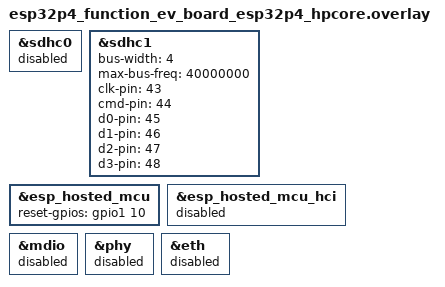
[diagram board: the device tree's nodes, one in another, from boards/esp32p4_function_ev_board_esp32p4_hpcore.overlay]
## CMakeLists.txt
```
cmake_minimum_required(VERSION 3.20.0)

find_package(Zephyr REQUIRED HINTS $ENV{ZEPHYR_BASE})
project(stamp_p4_p1)

target_sources(app PRIVATE src/main.c)
```

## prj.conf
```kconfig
# Stamp-P4 Stamp-P4 P1 is a temporary control image.
CONFIG_NETWORKING=y
CONFIG_WIFI=y
CONFIG_WIFI_USAGE_MODE_STA=y
CONFIG_WIFI_ESP_HOSTED_MCU=y

# ESP-Hosted-MCU source 3f0d107 reports v2.12.12.
CONFIG_ESP_HOSTED_MCU_FW_VERSION_MAJOR=2
CONFIG_ESP_HOSTED_MCU_FW_VERSION_MINOR=12
CONFIG_ESP_HOSTED_MCU_FW_VERSION_PATCH=12
CONFIG_ESP_HOSTED_MCU_P1_TRANSPORT_TEST=y
CONFIG_ESP_HOSTED_MCU_LOG_LEVEL_INF=y

# IPv4/DHCP/ICMP are the only network functions needed by P1.
CONFIG_NET_IPV4=y
CONFIG_NET_IPV6=n
CONFIG_NET_ARP=y
CONFIG_NET_UDP=y
CONFIG_NET_DHCPV4=y
CONFIG_WIFI_STA_AUTO_DHCPV4=y
CONFIG_NET_MGMT_EVENT_INFO=y
CONFIG_NET_MGMT_EVENT_QUEUE_SIZE=32
CONFIG_NET_MGMT_EVENT_QUEUE_TIMEOUT=5000

# Leave enough room for Wi-Fi RPC events and 1500-byte data frames.
CONFIG_MAIN_STACK_SIZE=8192
CONFIG_SHELL_STACK_SIZE=6144
CONFIG_NET_RX_STACK_SIZE=4096
CONFIG_NET_TX_STACK_SIZE=2048
CONFIG_NET_MGMT_EVENT_STACK_SIZE=4096
CONFIG_NET_PKT_RX_COUNT=32
CONFIG_NET_PKT_TX_COUNT=24
CONFIG_NET_BUF_RX_COUNT=48
CONFIG_NET_BUF_TX_COUNT=32

# USB Serial/JTAG is the Function-EV board's selected console. The transport
# driver runs before the shell backend (priority 85 vs 90), so retain its
# startup markers until the shell can emit them.
CONFIG_LOG=y
CONFIG_LOG_MODE_DEFERRED=y
CONFIG_LOG_DEFAULT_LEVEL=3
CONFIG_SHELL=y
CONFIG_SHELL_BACKEND_SERIAL=y
CONFIG_SHELL_CMD_BUFF_SIZE=256
CONFIG_EARLY_CONSOLE=y
```

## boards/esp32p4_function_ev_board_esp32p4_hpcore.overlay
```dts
/*
 * Stamp-P4 P1 overlay.
 *
 * The Function-EV HP-core board support remains the base.  Only the
 * Stamp-P4 carrier wiring is changed here; this is not a copied board DTS.
 */

#include <zephyr/dt-bindings/gpio/gpio.h>

/* The Function-EV SD-card connector is not populated on Stamp-P4. */
&sdhc0 {
	status = "disabled";
};

/*
 * Stamp-AddOn C6 SDIO wiring on the Stamp-P4 carrier.
 *
 * GPIO42 is physical P4 GPIO42, represented by GPIO controller gpio1 offset
 * 10.  It is the C6 regulator enable/power-gate and reset-control path:
 * logical high enables the C6 rail, while logical low removes it.
 */
&sdhc1 {
	status = "okay";
	bus-width = <4>;
	max-bus-freq = <40000000>;
	clk-pin = <43>;
	cmd-pin = <44>;
	d0-pin = <45>;
	d1-pin = <46>;
	d2-pin = <47>;
	d3-pin = <48>;
};

&esp_hosted_mcu {
	reset-gpios = <&gpio1 10 GPIO_ACTIVE_HIGH>;
	status = "okay";
};

/* Bluetooth is outside P1 and is deliberately not brought up. */
&esp_hosted_mcu_hci {
	status = "disabled";
};

/* Ethernet is unrelated to this independent Wi-Fi host validation. */
&mdio {
	status = "disabled";
};

&phy {
	status = "disabled";
};

&eth {
	status = "disabled";
};
```

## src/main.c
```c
/*
 * Stamp-P4 P1 control application.
 *
 * P1 intentionally stops at the ESP-Hosted-MCU Wi-Fi path.  SSH, NTP, SMP,
 * and Bluetooth are not part of this image's acceptance claim.
 */

#include <errno.h>
#include <string.h>

#include <zephyr/kernel.h>
#include <zephyr/logging/log.h>
#include <zephyr/shell/shell.h>
#include <zephyr/sys/util.h>

#include <zephyr/net/icmp.h>
#include <zephyr/net/net_if.h>
#include <zephyr/net/net_ip.h>
#include <zephyr/net/net_mgmt.h>
#include <zephyr/net/wifi_mgmt.h>

LOG_MODULE_REGISTER(p1, LOG_LEVEL_INF);

#define P1_WIFI_EVENTS                                                                    \
	(NET_EVENT_WIFI_SCAN_RESULT | NET_EVENT_WIFI_SCAN_DONE |                          \
	 NET_EVENT_WIFI_CONNECT_RESULT | NET_EVENT_WIFI_DISCONNECT_RESULT)

static struct net_if *sta_iface;
static struct net_mgmt_event_callback wifi_cb;
static struct net_mgmt_event_callback ipv4_cb;

static uint32_t scan_result_count;
static bool scan_pending;
static bool connect_pending;
static bool associated;
static bool ipv4_ready;

static K_SEM_DEFINE(ping_reply_sem, 0, 1);
static struct net_icmp_ctx ping_ctx;

static int wifi_event_status(const struct net_mgmt_event_callback *cb)
{
	if (cb->info != NULL && cb->info_length >= sizeof(struct wifi_status)) {
		const struct wifi_status *status = cb->info;

		return status->status;
	}

	return -EIO;
}

static void p1_wifi_event_handler(struct net_mgmt_event_callback *cb,
				  uint64_t mgmt_event, struct net_if *iface)
{
	if (iface != sta_iface) {
		return;
	}

	switch (mgmt_event) {
	case NET_EVENT_WIFI_SCAN_RESULT: {
		const struct wifi_scan_result *result = cb->info;

		if (result == NULL ||
		    cb->info_length < sizeof(struct wifi_scan_result)) {
			LOG_ERR("P1 WIFI_SCAN_RESULT FAIL malformed");
			return;
		}

		scan_result_count++;
		LOG_INF("P1 WIFI_SCAN_RESULT index=%u ssid=%.*s channel=%u rssi=%d",
			scan_result_count, result->ssid_length,
			(const char *)result->ssid, result->channel, result->rssi);
		break;
	}

	case NET_EVENT_WIFI_SCAN_DONE: {
		int status = wifi_event_status(cb);

		scan_pending = false;
		if (status == 0) {
			LOG_INF("P1 STEP 09 WIFI_SCAN PASS results=%u",
				scan_result_count);
		} else {
			LOG_ERR("P1 STEP 09 WIFI_SCAN FAIL status=%d results=%u",
				status, scan_result_count);
		}
		break;
	}

	case NET_EVENT_WIFI_CONNECT_RESULT: {
		int status = wifi_event_status(cb);

		connect_pending = false;
		associated = (status == 0);
		ipv4_ready = false;
		if (associated) {
			LOG_INF("P1 STEP 10 ASSOCIATION PASS");
		} else {
			LOG_ERR("P1 STEP 10 ASSOCIATION FAIL status=%d", status);
		}
		break;
	}

	case NET_EVENT_WIFI_DISCONNECT_RESULT:
		associated = false;
		ipv4_ready = false;
		LOG_INF("P1 WIFI_DISCONNECT");
		break;

	default:
		break;
	}
}

static void p1_ipv4_event_handler(struct net_mgmt_event_callback *cb,
				  uint64_t mgmt_event, struct net_if *iface)
{
	char address[NET_IPV4_ADDR_LEN];
	struct net_in_addr *addr;

	ARG_UNUSED(cb);

	if (mgmt_event != NET_EVENT_IPV4_ADDR_ADD || iface != sta_iface) {
		return;
	}

	addr = net_if_ipv4_get_global_addr(iface, NET_ADDR_PREFERRED);
	if (addr == NULL) {
		LOG_ERR("P1 IPV4 FAIL no_preferred_address");
		return;
	}

	ipv4_ready = true;
	LOG_INF("P1 IPV4 PASS address=%s",
		net_addr_ntop(NET_AF_INET, addr, address, sizeof(address)));
}

static int cmd_p1_scan(const struct shell *sh, size_t argc, char **argv)
{
	struct wifi_scan_params params = {0};
	int ret;

	ARG_UNUSED(argc);
	ARG_UNUSED(argv);

	if (sta_iface == NULL) {
		shell_error(sh, "Wi-Fi station interface is not ready");
		return -ENODEV;
	}
	if (scan_pending) {
		shell_error(sh, "scan already pending");
		return -EBUSY;
	}

	scan_result_count = 0;
	scan_pending = true;
	params.scan_type = WIFI_SCAN_TYPE_ACTIVE;
	params.bands = BIT(WIFI_FREQ_BAND_2_4_GHZ);
	params.max_bss_cnt = 0;

	LOG_INF("P1 STEP 09 WIFI_SCAN BEGIN");
	ret = net_mgmt(NET_REQUEST_WIFI_SCAN, sta_iface, &params, sizeof(params));
	if (ret != 0) {
		scan_pending = false;
		LOG_ERR("P1 STEP 09 WIFI_SCAN FAIL request_errno=%d", ret);
		shell_error(sh, "scan request failed: %d", ret);
		return ret;
	}

	shell_print(sh, "scan requested");
	return 0;
}

static int cmd_p1_connect(const struct shell *sh, size_t argc, char **argv)
{
	struct wifi_connect_req_params params = {0};
	size_t ssid_len = strlen(argv[1]);
	size_t psk_len = argc >= 3 ? strlen(argv[2]) : 0;
	int ret;

	if (sta_iface == NULL) {
		shell_error(sh, "Wi-Fi station interface is not ready");
		return -ENODEV;
	}
	if (ssid_len == 0 || ssid_len > WIFI_SSID_MAX_LEN) {
		shell_error(sh, "SSID length must be 1..%u", WIFI_SSID_MAX_LEN);
		return -EINVAL;
	}
	if (psk_len > 64) {
		shell_error(sh, "PSK length must be <= 64");
		return -EINVAL;
	}
	if (connect_pending) {
		shell_error(sh, "connect already pending");
		return -EBUSY;
	}

	params.ssid = (const uint8_t *)argv[1];
	params.ssid_length = (uint8_t)ssid_len;
	params.psk = psk_len ? (const uint8_t *)argv[2] : NULL;
	params.psk_length = (uint8_t)psk_len;
	params.security = psk_len ? WIFI_SECURITY_TYPE_PSK : WIFI_SECURITY_TYPE_NONE;
	params.band = WIFI_FREQ_BAND_2_4_GHZ;
	params.channel = WIFI_CHANNEL_ANY;
	params.timeout = 30;

	connect_pending = true;
	LOG_INF("P1 STEP 10 ASSOCIATION BEGIN ssid_length=%u",
		(unsigned int)ssid_len);
	ret = net_mgmt(NET_REQUEST_WIFI_CONNECT, sta_iface, &params, sizeof(params));
	if (ret != 0) {
		connect_pending = false;
		LOG_ERR("P1 STEP 10 ASSOCIATION FAIL request_errno=%d", ret);
		shell_error(sh, "connect request failed: %d", ret);
		return ret;
	}

	shell_print(sh, "connect requested; wait for ASSOCIATION and IPV4 markers");
	return 0;
}

static enum net_verdict p1_ping_handler(struct net_icmp_ctx *ctx,
					struct net_pkt *pkt,
					struct net_icmp_ip_hdr *ip_hdr,
					struct net_icmp_hdr *icmp_hdr,
					void *user_data)
{
	ARG_UNUSED(ctx);
	ARG_UNUSED(pkt);
	ARG_UNUSED(ip_hdr);
	ARG_UNUSED(icmp_hdr);
	ARG_UNUSED(user_data);

	k_sem_give(&ping_reply_sem);
	return NET_OK;
}

static int cmd_p1_ping(const struct shell *sh, size_t argc, char **argv)
{
	struct net_sockaddr_in destination = {0};
	struct net_icmp_ping_params params = {0};
	int ret;

	ARG_UNUSED(argc);

	if (!associated || !ipv4_ready) {
		shell_error(sh, "association and DHCPv4 address are required first");
		LOG_ERR("P1 STEP 11 PING FAIL ipv4_not_ready");
		return -ENETDOWN;
	}

	destination.sin_family = NET_AF_INET;
	ret = net_addr_pton(NET_AF_INET, argv[1], &destination.sin_addr);
	if (ret != 0) {
		shell_error(sh, "invalid IPv4 address: %s", argv[1]);
		LOG_ERR("P1 STEP 11 PING FAIL invalid_target=%s", argv[1]);
		return -EINVAL;
	}

	params.identifier = 0x4553;
	params.sequence = 1;
	params.data_size = 16;
	k_sem_reset(&ping_reply_sem);

	LOG_INF("P1 STEP 11 PING BEGIN target=%s", argv[1]);
	ret = net_icmp_send_echo_request(&ping_ctx, sta_iface,
					 (struct net_sockaddr *)&destination,
					 &params, NULL);
	if (ret != 0) {
		LOG_ERR("P1 STEP 11 PING FAIL send_errno=%d", ret);
		shell_error(sh, "ping send failed: %d", ret);
		return ret;
	}

	if (k_sem_take(&ping_reply_sem, K_SECONDS(5)) != 0) {
		LOG_ERR("P1 STEP 11 PING FAIL timeout");
		shell_error(sh, "ping timeout");
		return -ETIMEDOUT;
	}

	LOG_INF("P1 STEP 11 PING PASS target=%s", argv[1]);
	shell_print(sh, "ping reply received");
	return 0;
}

static int cmd_p1_status(const struct shell *sh, size_t argc, char **argv)
{
	ARG_UNUSED(argc);
	ARG_UNUSED(argv);

	shell_print(sh, "sta=%s associated=%s ipv4=%s scan_pending=%s connect_pending=%s",
		    sta_iface != NULL ? "ready" : "missing",
		    associated ? "yes" : "no", ipv4_ready ? "yes" : "no",
		    scan_pending ? "yes" : "no", connect_pending ? "yes" : "no");
	return 0;
}

SHELL_STATIC_SUBCMD_SET_CREATE(p1_commands,
	SHELL_CMD_ARG(scan, NULL, "Scan 2.4 GHz Wi-Fi", cmd_p1_scan, 1, 0),
	SHELL_CMD_ARG(connect, NULL, "Connect: p1 connect <ssid> [psk]",
		      cmd_p1_connect, 2, 1),
	SHELL_CMD_ARG(ping, NULL, "ICMPv4 ping: p1 ping <ipv4>",
		      cmd_p1_ping, 2, 1),
	SHELL_CMD_ARG(status, NULL, "Show P1 state", cmd_p1_status, 1, 0),
	SHELL_SUBCMD_SET_END
);

SHELL_CMD_REGISTER(p1, &p1_commands, "Stamp-P4 P1 controls", NULL);

int main(void)
{
	int ret;

	sta_iface = net_if_get_wifi_sta();
	if (sta_iface == NULL) {
		LOG_ERR("P1 READY FAIL wifi_sta_interface_missing");
		return 0;
	}

	net_mgmt_init_event_callback(&wifi_cb, p1_wifi_event_handler, P1_WIFI_EVENTS);
	net_mgmt_add_event_callback(&wifi_cb);
	net_mgmt_init_event_callback(&ipv4_cb, p1_ipv4_event_handler,
				     NET_EVENT_IPV4_ADDR_ADD);
	net_mgmt_add_event_callback(&ipv4_cb);

	ret = net_icmp_init_ctx(&ping_ctx, NET_AF_INET,
				NET_ICMPV4_ECHO_REPLY, 0, p1_ping_handler);
	if (ret != 0) {
		LOG_ERR("P1 READY FAIL icmp_init_errno=%d", ret);
		return 0;
	}

	LOG_INF("P1 READY host=zephyr wifi=esp-hosted-mcu");
	LOG_INF("P1 COMMANDS p1 scan | p1 connect <ssid> [psk] | p1 ping <ipv4>");
	return 0;
}
```
